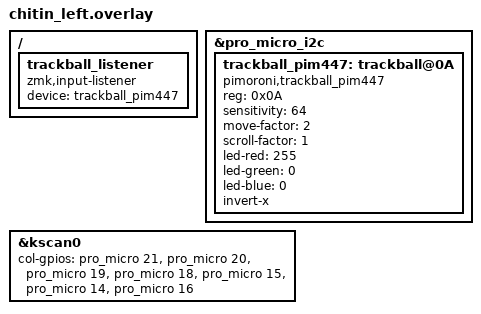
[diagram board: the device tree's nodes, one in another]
#include "chitin.dtsi"

&pro_micro_i2c {
    status = "okay";

    trackball_pim447: trackball@0A {
        compatible = "pimoroni,trackball_pim447";
        reg = <0x0A>;

        sensitivity = <64>;
        move-factor = <2>;
        scroll-factor = <1>;

        led-red = <255>;
        led-green = <0>;
        led-blue = <0>;

        /* Optional */
        invert-x;
        /* invert-y; */
    };
};

/ {
    trackball_listener {
        compatible = "zmk,input-listener";
        device = <&trackball_pim447>;
    };
};


&kscan0 {
        col-gpios 
            = <&pro_micro 21 GPIO_ACTIVE_HIGH>  // COL 0 (outer)
            , <&pro_micro 20 GPIO_ACTIVE_HIGH>  // COL 1 (pinky)
            , <&pro_micro 19 GPIO_ACTIVE_HIGH>  // COL 2 (ring)
            , <&pro_micro 18 GPIO_ACTIVE_HIGH>  // COL 3 (middle)
            , <&pro_micro 15 GPIO_ACTIVE_HIGH>  // COL 4 (index)
            , <&pro_micro 14 GPIO_ACTIVE_HIGH>  // COL 5 (inner)
            , <&pro_micro 16 GPIO_ACTIVE_HIGH>  // COL 6 (extra)
            ;
};
